AUTOSAR XML (schema 00046)
package /ComponentTypes
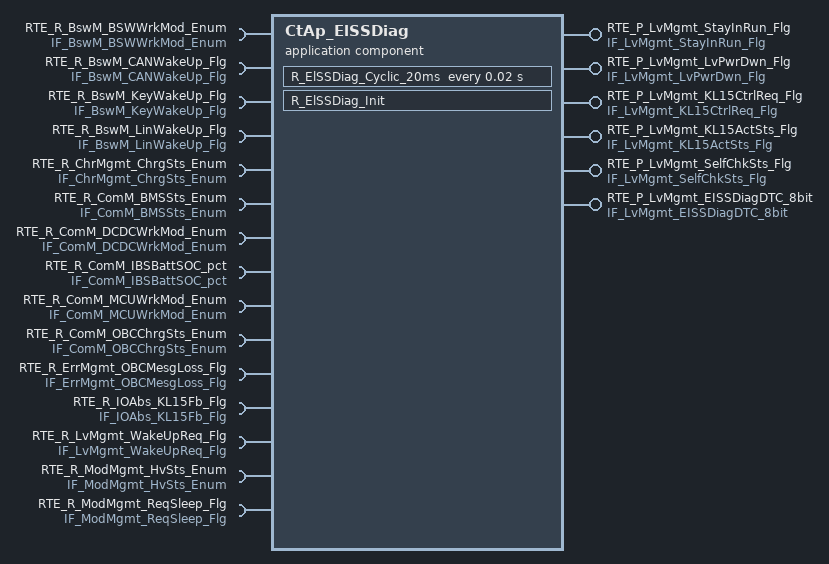
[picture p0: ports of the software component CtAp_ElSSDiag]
  application sw component type CtAp_ElSSDiag
    6 x provide port:
      RTE_P_LvMgmt_StayInRun_Flg: nonqueued-sender-com-spec{data-element=tec_LvMgmt_StayInRun_Flg, init-value=0}, provided-interface=IF_LvMgmt_StayInRun_Flg
      RTE_P_LvMgmt_LvPwrDwn_Flg: nonqueued-sender-com-spec{data-element=tec_LvMgmt_LvPwrDwn_Flg, init-value=0}, provided-interface=IF_LvMgmt_LvPwrDwn_Flg
      RTE_P_LvMgmt_KL15CtrlReq_Flg: nonqueued-sender-com-spec{data-element=tec_LvMgmt_KL15CtrlReq_Flg, init-value=0}, provided-interface=IF_LvMgmt_KL15CtrlReq_Flg
      RTE_P_LvMgmt_KL15ActSts_Flg: nonqueued-sender-com-spec{data-element=tec_LvMgmt_KL15ActSts_Flg, init-value=0}, provided-interface=IF_LvMgmt_KL15ActSts_Flg
      RTE_P_LvMgmt_SelfChkSts_Flg: nonqueued-sender-com-spec{data-element=tec_LvMgmt_SelfChkSts_Flg, init-value=0}, provided-interface=IF_LvMgmt_SelfChkSts_Flg
      RTE_P_LvMgmt_EISSDiagDTC_8bit: nonqueued-sender-com-spec{data-element=tec_LvMgmt_EISSDiagDTC_8bit, init-value=0}, provided-interface=IF_LvMgmt_EISSDiagDTC_8bit
    15 x require port:
      RTE_R_BswM_BSWWrkMod_Enum: nonqueued-receiver-com-spec{data-element=tec_BswM_BSWWrkMod_Enum, filter=data-filter-type=ALWAYS, init-value=0}, required-interface=IF_BswM_BSWWrkMod_Enum
      RTE_R_BswM_CANWakeUp_Flg: nonqueued-receiver-com-spec{data-element=tec_BswM_CANWakeUp_Flg, filter=data-filter-type=ALWAYS, init-value=0}, required-interface=IF_BswM_CANWakeUp_Flg
      RTE_R_BswM_KeyWakeUp_Flg: nonqueued-receiver-com-spec{data-element=tec_BswM_KeyWakeUp_Flg, filter=data-filter-type=ALWAYS, init-value=0}, required-interface=IF_BswM_KeyWakeUp_Flg
      RTE_R_BswM_LinWakeUp_Flg: nonqueued-receiver-com-spec{data-element=tec_BswM_LinWakeUp_Flg, filter=data-filter-type=ALWAYS, init-value=0}, required-interface=IF_BswM_LinWakeUp_Flg
      RTE_R_ChrMgmt_ChrgSts_Enum: nonqueued-receiver-com-spec{data-element=tec_ChrMgmt_ChrgSts_Enum, filter=data-filter-type=ALWAYS, init-value=0}, required-interface=IF_ChrMgmt_ChrgSts_Enum
      RTE_R_ComM_BMSSts_Enum: nonqueued-receiver-com-spec{data-element=tec_ComM_BMSSts_Enum, filter=data-filter-type=ALWAYS, init-value=0}, required-interface=IF_ComM_BMSSts_Enum
      RTE_R_ComM_DCDCWrkMod_Enum: nonqueued-receiver-com-spec{data-element=tec_ComM_DCDCWrkMod_Enum, filter=data-filter-type=ALWAYS, init-value=0}, required-interface=IF_ComM_DCDCWrkMod_Enum
      RTE_R_ComM_IBSBattSOC_pct: nonqueued-receiver-com-spec{data-element=tec_ComM_IBSBattSOC_pct, filter=data-filter-type=ALWAYS, init-value=0}, required-interface=IF_ComM_IBSBattSOC_pct
      RTE_R_ComM_MCUWrkMod_Enum: nonqueued-receiver-com-spec{data-element=tec_ComM_MCUWrkMod_Enum, filter=data-filter-type=ALWAYS, init-value=0}, required-interface=IF_ComM_MCUWrkMod_Enum
      RTE_R_ComM_OBCChrgSts_Enum: nonqueued-receiver-com-spec{data-element=tec_ComM_OBCChrgSts_Enum, filter=data-filter-type=ALWAYS, init-value=0}, required-interface=IF_ComM_OBCChrgSts_Enum
      RTE_R_ErrMgmt_OBCMesgLoss_Flg: nonqueued-receiver-com-spec{data-element=tec_ErrMgmt_OBCMesgLoss_Flg, filter=data-filter-type=ALWAYS, init-value=0}, required-interface=IF_ErrMgmt_OBCMesgLoss_Flg
      RTE_R_IOAbs_KL15Fb_Flg: nonqueued-receiver-com-spec{data-element=tec_IOAbs_KL15Fb_Flg, filter=data-filter-type=ALWAYS, init-value=0}, required-interface=IF_IOAbs_KL15Fb_Flg
      RTE_R_LvMgmt_WakeUpReq_Flg: nonqueued-receiver-com-spec{data-element=tec_LvMgmt_WakeUpReq_Flg, filter=data-filter-type=ALWAYS, init-value=0}, required-interface=IF_LvMgmt_WakeUpReq_Flg
      RTE_R_ModMgmt_HvSts_Enum: nonqueued-receiver-com-spec{data-element=tec_ModMgmt_HvSts_Enum, filter=data-filter-type=ALWAYS, init-value=0}, required-interface=IF_ModMgmt_HvSts_Enum
      RTE_R_ModMgmt_ReqSleep_Flg: nonqueued-receiver-com-spec{data-element=tec_ModMgmt_ReqSleep_Flg, filter=data-filter-type=ALWAYS, init-value=0}, required-interface=IF_ModMgmt_ReqSleep_Flg
    behavior CtAp_ElSSDiag_InternalBehavior
      init event CtAp_ElSSDiag_InitEvent: start-on-event=R_ElSSDiag_Init
      timing event TMT_R_ElSSDiag_Cyclic_20ms: start-on-event=R_ElSSDiag_Cyclic_20ms, period=0.02
      runnable R_ElSSDiag_Init
      runnable R_ElSSDiag_Cyclic_20ms
        data-receive-point-by-arguments:
          15 x access:
            REC_RTE_R_BswM_BSWWrkMod_Enum_tec_BswM_BSWWrkMod_Enum: accessed-variable=RTE_R_BswM_BSWWrkMod_Enum.tec_BswM_BSWWrkMod_Enum
            REC_RTE_R_BswM_CANWakeUp_Flg_tec_BswM_CANWakeUp_Flg: accessed-variable=RTE_R_BswM_CANWakeUp_Flg.tec_BswM_CANWakeUp_Flg
            REC_RTE_R_BswM_KeyWakeUp_Flg_tec_BswM_KeyWakeUp_Flg: accessed-variable=RTE_R_BswM_KeyWakeUp_Flg.tec_BswM_KeyWakeUp_Flg
            REC_RTE_R_BswM_LinWakeUp_Flg_tec_BswM_LinWakeUp_Flg: accessed-variable=RTE_R_BswM_LinWakeUp_Flg.tec_BswM_LinWakeUp_Flg
            REC_RTE_R_ChrMgmt_ChrgSts_Enum_tec_ChrMgmt_ChrgSts_Enum: accessed-variable=RTE_R_ChrMgmt_ChrgSts_Enum.tec_ChrMgmt_ChrgSts_Enum
            REC_RTE_R_ComM_BMSSts_Enum_tec_ComM_BMSSts_Enum: accessed-variable=RTE_R_ComM_BMSSts_Enum.tec_ComM_BMSSts_Enum
            REC_RTE_R_ComM_DCDCWrkMod_Enum_tec_ComM_DCDCWrkMod_Enum: accessed-variable=RTE_R_ComM_DCDCWrkMod_Enum.tec_ComM_DCDCWrkMod_Enum
            REC_RTE_R_ComM_IBSBattSOC_pct_tec_ComM_IBSBattSOC_pct: accessed-variable=RTE_R_ComM_IBSBattSOC_pct.tec_ComM_IBSBattSOC_pct
            REC_RTE_R_ComM_MCUWrkMod_Enum_tec_ComM_MCUWrkMod_Enum: accessed-variable=RTE_R_ComM_MCUWrkMod_Enum.tec_ComM_MCUWrkMod_Enum
            REC_RTE_R_ComM_OBCChrgSts_Enum_tec_ComM_OBCChrgSts_Enum: accessed-variable=RTE_R_ComM_OBCChrgSts_Enum.tec_ComM_OBCChrgSts_Enum
            REC_RTE_R_ErrMgmt_OBCMesgLoss_Flg_tec_ErrMgmt_OBCMesgLoss_Flg: accessed-variable=RTE_R_ErrMgmt_OBCMesgLoss_Flg.tec_ErrMgmt_OBCMesgLoss_Flg
            REC_RTE_R_IOAbs_KL15Fb_Flg_tec_IOAbs_KL15Fb_Flg: accessed-variable=RTE_R_IOAbs_KL15Fb_Flg.tec_IOAbs_KL15Fb_Flg
            REC_RTE_R_LvMgmt_WakeUpReq_Flg_tec_LvMgmt_WakeUpReq_Flg: accessed-variable=RTE_R_LvMgmt_WakeUpReq_Flg.tec_LvMgmt_WakeUpReq_Flg
            REC_RTE_R_ModMgmt_HvSts_Enum_tec_ModMgmt_HvSts_Enum: accessed-variable=RTE_R_ModMgmt_HvSts_Enum.tec_ModMgmt_HvSts_Enum
            REC_RTE_R_ModMgmt_ReqSleep_Flg_tec_ModMgmt_ReqSleep_Flg: accessed-variable=RTE_R_ModMgmt_ReqSleep_Flg.tec_ModMgmt_ReqSleep_Flg
        data-send-points:
          6 x access:
            SEND_RTE_P_LvMgmt_EISSDiagDTC_8bit_tec_LvMgmt_EISSDiagDTC_8bit: accessed-variable=RTE_P_LvMgmt_EISSDiagDTC_8bit.tec_LvMgmt_EISSDiagDTC_8bit
            SEND_RTE_P_LvMgmt_KL15ActSts_Flg_tec_LvMgmt_KL15ActSts_Flg: accessed-variable=RTE_P_LvMgmt_KL15ActSts_Flg.tec_LvMgmt_KL15ActSts_Flg
            SEND_RTE_P_LvMgmt_KL15CtrlReq_Flg_tec_LvMgmt_KL15CtrlReq_Flg: accessed-variable=RTE_P_LvMgmt_KL15CtrlReq_Flg.tec_LvMgmt_KL15CtrlReq_Flg
            SEND_RTE_P_LvMgmt_LvPwrDwn_Flg_tec_LvMgmt_LvPwrDwn_Flg: accessed-variable=RTE_P_LvMgmt_LvPwrDwn_Flg.tec_LvMgmt_LvPwrDwn_Flg
            SEND_RTE_P_LvMgmt_SelfChkSts_Flg_tec_LvMgmt_SelfChkSts_Flg: accessed-variable=RTE_P_LvMgmt_SelfChkSts_Flg.tec_LvMgmt_SelfChkSts_Flg
            SEND_RTE_P_LvMgmt_StayInRun_Flg_tec_LvMgmt_StayInRun_Flg: accessed-variable=RTE_P_LvMgmt_StayInRun_Flg.tec_LvMgmt_StayInRun_Flg
  swc implementation CtAp_ElSSDiag_Implementation: behavior=CtAp_ElSSDiag_InternalBehavior
    code-descriptors:
      code Default: artifact-descriptors=autosar-engineering-object=category=SWOBJ
